VERSION ""

NS_ :

BS_:

BU_: Vehicle QuickChargeStation

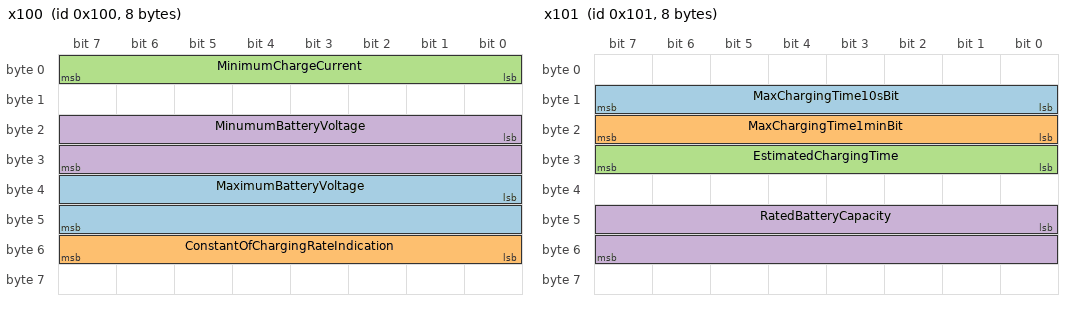
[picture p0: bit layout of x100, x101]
BO_ 256 x100: 8 Vehicle
 SG_ MaximumBatteryVoltage : 32|16@1+ (1,0) [0|600] "V" Vector__XXX
 SG_ ConstantOfChargingRateIndication : 48|8@1+ (1,0) [0|100] "%" Vector__XXX
 SG_ MinimumChargeCurrent : 0|8@1+ (1,0) [0|255] "A" Vector__XXX
 SG_ MinumumBatteryVoltage : 16|16@1+ (1,0) [0|600] "V" Vector__XXX

BO_ 257 x101: 8 Vehicle
 SG_ MaxChargingTime10sBit : 8|8@1+ (10,0) [0|2540] "seconds" Vector__XXX
 SG_ MaxChargingTime1minBit : 16|8@1+ (1,0) [0|255] "minutes" Vector__XXX
 SG_ EstimatedChargingTime : 24|8@1+ (1,0) [0|254] "minutes" Vector__XXX
 SG_ RatedBatteryCapacity : 40|16@1+ (0.1,0) [0|100] "kWh" Vector__XXX

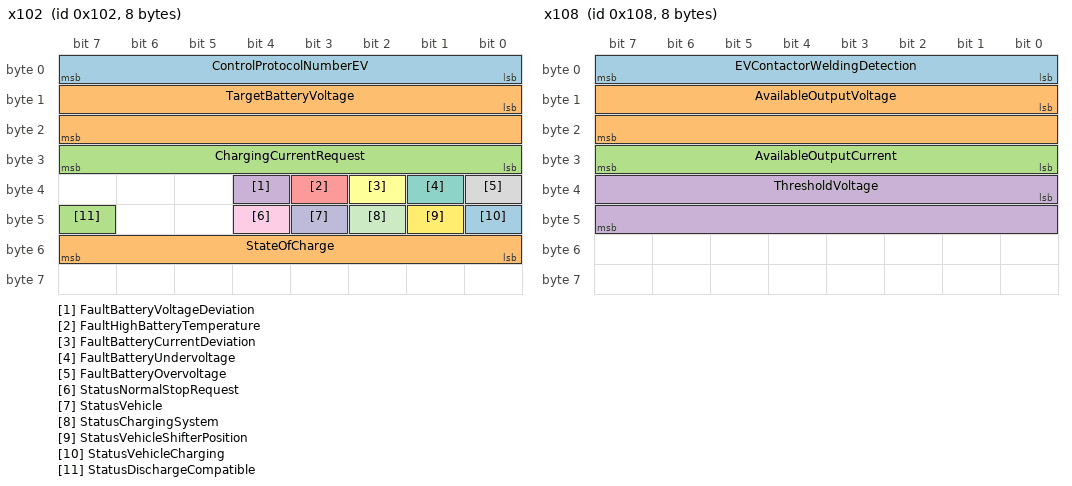
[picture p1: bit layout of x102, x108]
BO_ 258 x102: 8 Vehicle
 SG_ ControlProtocolNumberEV : 0|8@1+ (1,0) [0|255] "" Vector__XXX
 SG_ TargetBatteryVoltage : 8|16@1+ (1,0) [0|600] "V" Vector__XXX
 SG_ ChargingCurrentRequest : 24|8@1+ (1,0) [0|255] "A" Vector__XXX
 SG_ FaultBatteryVoltageDeviation : 36|1@1+ (1,0) [0|1] "status" Vector__XXX
 SG_ FaultHighBatteryTemperature : 35|1@1+ (1,0) [0|1] "status" Vector__XXX
 SG_ FaultBatteryCurrentDeviation : 34|1@1+ (1,0) [0|1] "status" Vector__XXX
 SG_ FaultBatteryUndervoltage : 33|1@1+ (1,0) [0|1] "status" Vector__XXX
 SG_ FaultBatteryOvervoltage : 32|1@1+ (1,0) [0|1] "status" Vector__XXX
 SG_ StatusNormalStopRequest : 44|1@1+ (1,0) [0|1] "status" Vector__XXX
 SG_ StatusVehicle : 43|1@1+ (1,0) [0|1] "status" Vector__XXX
 SG_ StatusChargingSystem : 42|1@1+ (1,0) [0|1] "status" Vector__XXX
 SG_ StatusVehicleShifterPosition : 41|1@1+ (1,0) [0|1] "status" Vector__XXX
 SG_ StatusVehicleCharging : 40|1@1+ (1,0) [0|1] "status" Vector__XXX
 SG_ StateOfCharge : 48|8@1+ (1,0) [0|100] "%" Vector__XXX
 SG_ StatusDischargeCompatible : 47|1@1+ (1,0) [0|0] "" Vector__XXX

BO_ 264 x108: 8 QuickChargeStation
 SG_ EVContactorWeldingDetection : 0|8@1+ (1,0) [0|1] "" Vector__XXX
 SG_ AvailableOutputVoltage : 8|16@1+ (1,0) [0|600] "V" Vector__XXX
 SG_ AvailableOutputCurrent : 24|8@1+ (1,0) [0|255] "A" Vector__XXX
 SG_ ThresholdVoltage : 32|16@1+ (1,0) [0|600] "V" Vector__XXX

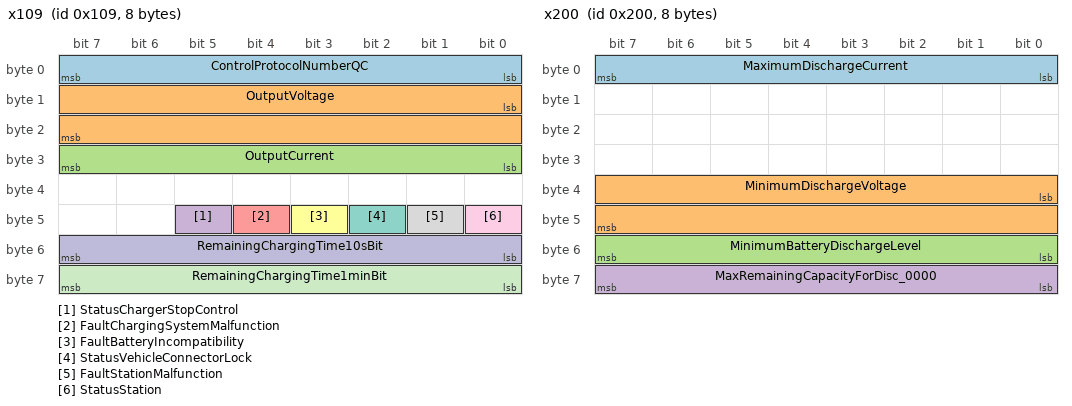
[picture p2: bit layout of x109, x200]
BO_ 265 x109: 8 QuickChargeStation
 SG_ ControlProtocolNumberQC : 0|8@1+ (1,0) [0|255] "" Vector__XXX
 SG_ OutputVoltage : 8|16@1+ (1,0) [0|600] "V" Vector__XXX
 SG_ OutputCurrent : 24|8@1+ (1,0) [0|255] "A" Vector__XXX
 SG_ StatusChargerStopControl : 45|1@1+ (1,0) [0|1] "status" Vector__XXX
 SG_ FaultChargingSystemMalfunction : 44|1@1+ (1,0) [0|1] "status" Vector__XXX
 SG_ FaultBatteryIncompatibility : 43|1@1+ (1,0) [0|1] "status" Vector__XXX
 SG_ StatusVehicleConnectorLock : 42|1@1+ (1,0) [0|1] "status" Vector__XXX
 SG_ FaultStationMalfunction : 41|1@1+ (1,0) [0|1] "status" Vector__XXX
 SG_ StatusStation : 40|1@1+ (1,0) [0|1] "status" Vector__XXX
 SG_ RemainingChargingTime10sBit : 48|8@1+ (10,0) [0|2540] "seconds" Vector__XXX
 SG_ RemainingChargingTime1minBit : 56|8@1+ (1,0) [0|255] "minutes" Vector__XXX

BO_ 512 x200: 8 Vehicle
 SG_ MaximumDischargeCurrent : 0|8@1+ (1,-255) [-255|255] "A" Vector__XXX
 SG_ MinimumDischargeVoltage : 32|16@1+ (1,0) [0|640] "V" Vector__XXX
 SG_ MinimumBatteryDischargeLevel : 48|8@1+ (0.1,0) [0|255] "kWh" Vector__XXX
 SG_ MaxRemainingCapacityForDisc_0000 : 56|8@1+ (0.1,0) [0|255] "kWh" Vector__XXX

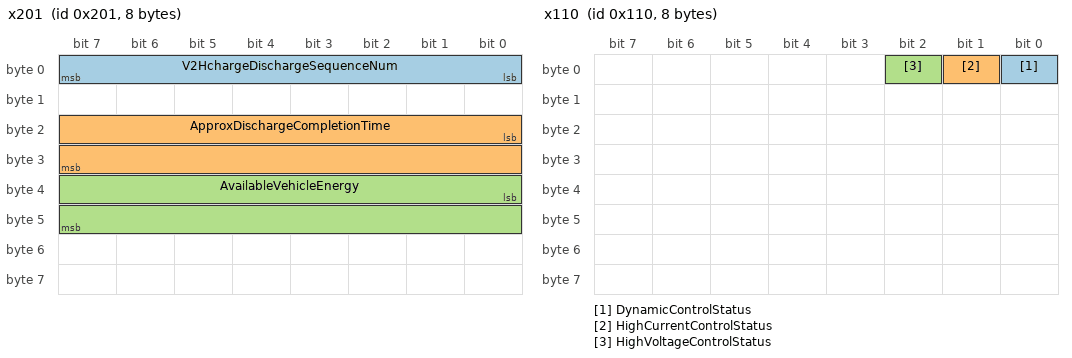
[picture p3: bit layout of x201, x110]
BO_ 513 x201: 8 Vehicle
 SG_ V2HchargeDischargeSequenceNum : 0|8@1+ (1,0) [0|0] "" Vector__XXX
 SG_ ApproxDischargeCompletionTime : 16|16@1+ (1,0) [0|0] "" Vector__XXX
 SG_ AvailableVehicleEnergy : 32|16@1+ (1,0) [0|0] "" Vector__XXX

BO_ 1792 x700: 8 Vehicle
 SG_ AutomakerCode : 0|8@1+ (1,0) [0|255] "-" Vector__XXX
 SG_ OptionalContent : 8|56@1+ (1,0) [0|0] "" Vector__XXX

BO_ 272 x110: 8 Vehicle
 SG_ DynamicControlStatus : 0|1@1+ (1,0) [0|1] "status" Vector__XXX
 SG_ HighCurrentControlStatus : 1|1@1+ (1,0) [0|1] "status" Vector__XXX
 SG_ HighVoltageControlStatus : 2|1@1+ (1,0) [0|1] "status" Vector__XXX

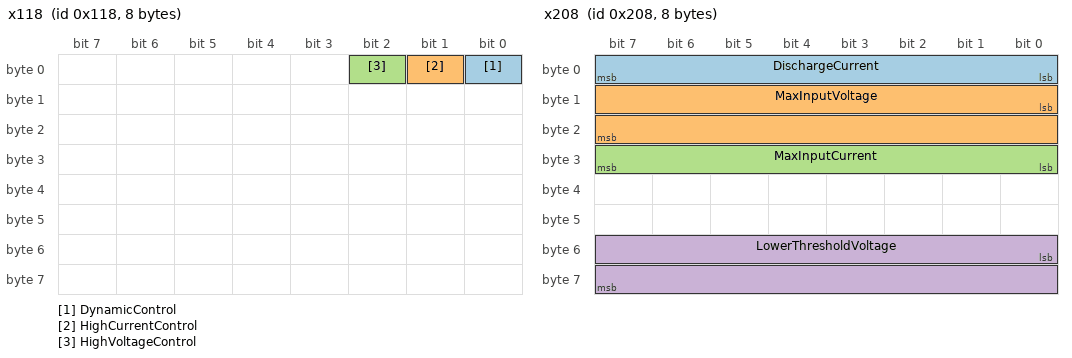
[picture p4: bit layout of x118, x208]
BO_ 280 x118: 8 QuickChargeStation
 SG_ DynamicControl : 0|1@1+ (1,0) [0|1] "" Vector__XXX
 SG_ HighCurrentControl : 1|1@1+ (1,0) [0|1] "" Vector__XXX
 SG_ HighVoltageControl : 2|1@1+ (1,0) [0|1] "" Vector__XXX

BO_ 520 x208: 8 QuickChargeStation
 SG_ DischargeCurrent : 0|8@1+ (1,-255) [-255|0] "A" Vector__XXX
 SG_ MaxInputVoltage : 8|16@1+ (1,0) [0|600] "V" Vector__XXX
 SG_ MaxInputCurrent : 24|8@1+ (1,-255) [-255|0] "A" Vector__XXX
 SG_ LowerThresholdVoltage : 48|16@1+ (1,0) [0|600] "V" Vector__XXX

BO_ 521 x209: 8 QuickChargeStation
 SG_ Sequence : 0|8@1+ (1,0) [0|255] "" Vector__XXX
 SG_ RemainingDischargeTime : 8|16@1+ (1,0) [0|65535] "" Vector__XXX

CM_ BO_ 256 "100ms Charge parameters";
CM_ SG_ 256 MaximumBatteryVoltage "The maximum battery voltage value at the vehicle inlet terminals, at which the station stops charging to protect the vehicle battery. Raised to 1200 V in Chademo 2.0";
CM_ SG_ 256 ConstantOfChargingRateIndication "Fixed value for charging rate indication which is the maximum charging rate (100%) of vehicle battery. Should be fixed at 0x64 (100 %)";
CM_ SG_ 256 MinumumBatteryVoltage "The minimum battery voltage for the vehicle. Added in later Chademo versions for V2X";
CM_ BO_ 257 "100ms Calculated charge time and SoC";
CM_ SG_ 257 MaxChargingTime10sBit "Maximum charging time permited by EV, set by10s";
CM_ SG_ 257 MaxChargingTime1minBit "Maximum charging time permited by EV, set by minute";
CM_ SG_ 257 EstimatedChargingTime "Estimated remaining time before the end of charging calculated by EV (Added in CHAdeMO1.0.1)";
CM_ SG_ 257 RatedBatteryCapacity "Rated capacity of battery (Added in CHAdeMO1.0.1)";
CM_ BO_ 258 "100ms Signals for error marking";
CM_ SG_ 258 ControlProtocolNumberEV "Software version of control protocol to which EV corresponds";
CM_ SG_ 258 TargetBatteryVoltage "Target charging voltage at the vehicle inlet terminals. Raised to 1200 V max in Chademo 2.0";
CM_ SG_ 258 ChargingCurrentRequest "Current value requested by EV during charging";
CM_ SG_ 258 FaultBatteryVoltageDeviation "Status flag indicating whether or not the vehicle battery voltage deviates from the output voltage measured by the station

Flag indicating the result of judgment regarding the difference between measured voltage of on- board battery and �Present output voltage� measured by the charger.";
CM_ SG_ 258 FaultHighBatteryTemperature "Status flag indicating whether or not the temperature of vehicle battery exceeds the maximum limit";
CM_ SG_ 258 FaultBatteryCurrentDeviation "Status flag indicating whether or not the output current deviates from EV requested current

 If the EVSE�s output exceeds the maximum charge current continually, the flag shall be changed to 1. The overcurrent threshold shall be set at 10 A (absolute value) or more, and the time threshold shall be set at 5sec or more
- If the EVSE�s input exceeds the range of the maximum discharge current continually, the flag shall be changed to 1. The overcurrent threshold shall be set at 10 A (absolute value) or more and the time threshold shall be set at 5sec or more
- The vehicle charge/discharge enabled and switch (k) shall be turned off at the same time
- Regardless of the condition of the opto-coupler (j), if this flag is 1, it shall be considered as the vehicle�s request to stop charging/discharging, and the EVSE shall move to the stop control.";
CM_ SG_ 258 FaultBatteryUndervoltage "Status flag indicating whether or not the vehicle battery voltage is less than the lower limit specified by EV";
CM_ SG_ 258 FaultBatteryOvervoltage "Status flag indicating whether or not the vehicle battery voltage exceeds the maximum limit specified by EV

Regardless of opto-coupler (j) status, the EVSE shall regard this flag as charging termination order from the vehicle if it is equal to 1, and stop charging.";
CM_ SG_ 258 StatusNormalStopRequest "Status flag indicating the request of EV to stop charging control

This value shall be updated until initial value of �Charging current request� is set. Do not update this value after initial value transmission.";
CM_ SG_ 258 StatusVehicle "Status flag indicating the EV contactor status

Set the flag to 0 when the vehicle relay is closed, and set as 1 after the termination of welding detection. - Set the flag to 0 when the vehicle relay is closed, and set as 1 after the termination of welding detection.";
CM_ SG_ 258 StatusChargingSystem "Status flag indicating malfunction caused by EV or the station, and detected by EV

Update as needed, and hold �1� after the malfunction is determined. � Regardless of the condition of the opto-coupler (j), if this flag is 0, it shall be considered as the vehicle's request to stop charging/discharging, and the EVSE shall move to the stop control.";
CM_ SG_ 258 StatusVehicleShifterPosition "Status flag indicating the shift lever position ";
CM_ SG_ 258 StatusVehicleCharging "Status flag indicating charge permission status of EV

After CAN communication starts and the vehicle sends the EVSE data required for prior to a start of charging/discharging, change the flag 0 to 1. � Change this flag 1 to 0 when the vehicle sends the �charging/discharging stop� notification to the EVSE. Regardless of the condition of the opto-coupler (j), if this flag is 0, it shall be considered as the vehicle's request to stop charging/discharging, and the EVSE shall move to the stop control.� When this flag is 0, the insulation test shall not be conducted.";
CM_ SG_ 258 StateOfCharge "Charging rate of vehicle battery";
CM_ SG_ 258 StatusDischargeCompatible "Flag indicating the vehicle is compatible with V2X

The value shall be set from the first time of the CAN communication, and it shall not be updated. However, if it is inevitable to reset the value, e.g. for battery protection, the value is updated from 1 to 0 and only discharging shall be prohibited.";
CM_ BO_ 264 "100ms Charge parameters";
CM_ SG_ 264 EVContactorWeldingDetection "Identifier indicating whether or not the station deals with EV contactor welding detection";
CM_ SG_ 264 AvailableOutputVoltage "Maximum output voltage value at the vehicle connector terminals. Raised to 1200 V max in Chademo 2.0

Set the number from initial CAN data transmission and do not update it. If the EVSE receives �target battery voltage� exceeding this value from the vehicle, regard this situation as �Battery incompatible� and shift to charge termination process.";
CM_ SG_ 264 AvailableOutputCurrent "Maximum output current value of the station

This value shall be set from the initial CAN communication. The initial value shall be the maximum current that can be output by the EVSE, and during the charging/discharging, the value shall be updated from time to time as the current which can be output by the EVSE. The smaller value between this value and the �maximum charge current� shall be set as the target charge current.";
CM_ SG_ 264 ThresholdVoltage "Threshold voltage to stop the charging process in order to protect vehicle battery

This flag may be updated until the initial value of charging current request is sent from the vehicle.� The EVSE shall compare vehicle CAN �maximum battery voltage� with charger CAN �available output voltage,� set the lower value to this value. � When circuit voltage reaches to this value, the EVSE stops charging output.";
CM_ BO_ 265 "100ms Signals for error marking";
CM_ SG_ 265 ControlProtocolNumberQC "Software version number of control protocol or charging sequences that the station deal with";
CM_ SG_ 265 OutputVoltage "Supply voltage value of the output circuit in the station. Raised to 1200 V max in Chademo 2.0";
CM_ SG_ 265 OutputCurrent "Supply current value of the output circuit in the station";
CM_ SG_ 265 StatusChargerStopControl "Status flag indicating whether or not the status proceeds with shutdown process

Change this flag to 0 from 1 after shifting to the start of charging control. Also, both the timing that the �charging stop control (H�109.5.5)� is changed to 0 from 1 and the timing that the �charger status (H�109.5.0)� is changed to 1 from 0 shall be in an exclusive relation. Set 1 from 0 to this flag in case the charging sequence shifts to stop process (including a state of stop process).";
CM_ SG_ 265 FaultChargingSystemMalfunction "Status flag indicating whether or not there is a problem with EV, such as improper connection

Charger shall detect error and shall shift to error stop process in case this flag is set to 1.";
CM_ SG_ 265 FaultBatteryIncompatibility "Status flag indicating the compatibility of vehicle battery with the output voltage of station

Set 1 to this flag in case �target battery voltage (H�102.1, H�102.2)� of vehicle exceeds �available output voltage (H�108.1, H�108.2)� or �Minimum battery voltage (H�100.2, H� 100.3)� of vehicle is below �output voltage lower limit.\" Charger shall detect error and shall shift to error stop process in case this flag is set to 1.";
CM_ SG_ 265 StatusVehicleConnectorLock "Status flag indicating the electromagnetic lock status of the vehicle

Set 1 to this flag when vehicle permits charger to charge and/or voltage in output circuit exceeds 10 V. Set 0 to this flag when vehicle prohibits charger to charge and/or voltage in output circuit is less than or equal to 10 V.";
CM_ SG_ 265 FaultStationMalfunction "Status flag indicating whether or not there is a malfunction caused by the station

Charger shall detect error and shall shift to error stop process in case this flag is set to 1.";
CM_ SG_ 265 StatusStation "Status flag indicating the energy transfer from the station

Set 0 to this flag before charging (e.g., initial value, during insulation test) and at the end of the charging (shifting to stop process and charging current decreases less than or equal to 5 A). Set 1 to this flag during charging";
CM_ SG_ 265 RemainingChargingTime10sBit "Remaining time before the end of charging (counted by 10 s)";
CM_ SG_ 265 RemainingChargingTime1minBit "Remaining time before the end of charging (counted by minutes)";
CM_ BO_ 512 "100ms (For V2X)";
CM_ SG_ 512 MaximumDischargeCurrent "Maximum discharge current that the vehicle permits to the EVSE.

This value shall be set according to the vehicle�s battery condition in consideration of the following conditions. The initial value shall be set at 0 and the value shall be constantly updated (only when it is inevitable, e.g., for battery protection).
At the time of the Charge/discharge mode, discharging shall be implemented with this value as the upper limit. � There are vehicles of the models before the V2H guideline 1.1 whose initial value is not set at 0. The control error shall be avoided by masking the initial value etc. � If EVSE has a bigger this value than Available input current, it does not use stopping judgment.";
CM_ SG_ 512 MinimumDischargeVoltage "Minimum voltage that the vehicle can discharge.

This value can be updated until the switch (k) is turned off. Once this value is set, it shall not be updated.";
CM_ SG_ 512 MinimumBatteryDischargeLevel "Either sent as %, kWh or 0. Roughly 30% of RatedBatteryCapacity. This value shall be set as the minimum discharge voltage of the vehicle battery. If this value is not used, 0x00 shall be set. When the EVSE reaches this value, the EVSE prohibits only discharge. (But the EVSE can continue charge.) However, in case of the vehicles before the V2H guideline 1.0, the unit of this value is kWh.";
CM_ SG_ 512 MaxRemainingCapacityForDisc_0000 "(Optional) Maximum battery capacity with which the vehicle permits discharging.

This value shall be set as the maximum discharging capacity of the vehicle battery. � If this value is not used, 0x00 shall be set.When the EVSE reaches this value, the EVSE prohibits discharge. (But the EVSE can continue charge.) However, in case of the vehicles before the V2H guideline 1.0, the unit of this value is kWh. Using the next expression, the EVSE converts a unit into %. Maximum charging rate for charging [%] = Maximum remaining battery capacity for charging [kWh] � Total battery capacity [kWh] � 100 [%]. In addition, the EVSE cuts off a decimal and applies a unit conversion result. � When the EVSE receives 0, it shall not be used with the assumption that the value is not set. � The EVSE shall not be used until the switch (k) is turned on.";
CM_ BO_ 513 "100ms (For V2X)";
CM_ SG_ 513 ApproxDischargeCompletionTime "(Optional)";
CM_ SG_ 513 AvailableVehicleEnergy "(Optional)";
CM_ BO_ 1792 "100ms";
CM_ SG_ 1792 OptionalContent "Content conform to each manufacturer's optional specification";
CM_ BO_ 272 "100ms (Chademo v2.0 only)";
CM_ SG_ 272 DynamicControlStatus "When this bit is 1 dynamic control is allowed. Dynamic Control = Charging station can increase of decrease \"available output current\" during charging.";
CM_ BO_ 280 "100ms (Chademo v2.0 only)";
CM_ SG_ 280 DynamicControl "Dynamic charging is supported on Chademo v2.0";
CM_ BO_ 520 "100ms (For V2X)";
CM_ SG_ 520 DischargeCurrent "The circuit current measured by the EVSE";
CM_ SG_ 520 MaxInputVoltage "The maximum voltage with which the EVSE can operate";
CM_ SG_ 520 MaxInputCurrent "The current with which the EVSE stops discharging in order to protect the circuit";
CM_ SG_ 520 LowerThresholdVoltage "The voltage with which the EVSE shall stop when the vehicle cannot stop at the minimum discharge voltage of the vehicle system due to a fault";
CM_ BO_ 521 "100ms (For V2X)";
BA_DEF_ SG_  "SystemSignalLongSymbol" STRING ;
BA_DEF_DEF_  "SystemSignalLongSymbol" "";
BA_ "SystemSignalLongSymbol" SG_ 512 MaxRemainingCapacityForDisc_0000 "MaxRemainingCapacityForDischarging";
VAL_ 258 ControlProtocolNumberEV 1 "Chademo v1.0" 2 "Chademo v1.1" 3 "Chademo v2.0" ;
VAL_ 258 FaultBatteryVoltageDeviation 0 "Normal" 1 "Fault" ;
VAL_ 258 FaultHighBatteryTemperature 0 "Normal" 1 "Fault" ;
VAL_ 258 FaultBatteryCurrentDeviation 0 "Normal" 1 "Fault" ;
VAL_ 258 FaultBatteryUndervoltage 0 "Normal" 1 "Fault" ;
VAL_ 258 FaultBatteryOvervoltage 0 "Normal" 1 "Fault" ;
VAL_ 258 StatusNormalStopRequest 0 "No request" 1 "Request to stop" ;
VAL_ 258 StatusVehicle 0 "EV contactor closed or during welding detection" 1 "EV contactor open or welding detection finished" ;
VAL_ 258 StatusChargingSystem 0 "Normal" 1 "Fault" ;
VAL_ 258 StatusVehicleShifterPosition 0 "Parked" 1 "Other position" ;
VAL_ 258 StatusVehicleCharging 0 "Disabled" 1 "Enabled" ;
VAL_ 258 StatusDischargeCompatible 0 "Incompatible" 1 "Compatible" ;
VAL_ 264 EVContactorWeldingDetection 0 "Not supported" 1 "Supporting vehicle welding detection" ;
VAL_ 265 StatusChargerStopControl 0 "Operating" 1 "Shutdown or stop charging" ;
VAL_ 265 FaultChargingSystemMalfunction 0 "Normal" 1 "Malfunction" ;
VAL_ 265 FaultBatteryIncompatibility 0 "Compatible" 1 "Not compatible" ;
VAL_ 265 StatusVehicleConnectorLock 0 "Unlocked" 1 "Locked" ;
VAL_ 265 FaultStationMalfunction 0 "Normal" 1 "Fault" ;
VAL_ 265 StatusStation 0 "Standby" 1 "Charging" ;
VAL_ 272 DynamicControlStatus 0 "Disabled" 1 "Enabled" ;
VAL_ 272 HighCurrentControlStatus 0 "Disabled" 1 "Enabled" ;
VAL_ 272 HighVoltageControlStatus 0 "Disabled" 1 "Enabled" ;
VAL_ 280 DynamicControl 0 "Disabled" 1 "Enabled" ;
VAL_ 280 HighCurrentControl 0 "Disabled" 1 "Enabled" ;
VAL_ 280 HighVoltageControl 0 "Disabled" 1 "Enabled" ;
